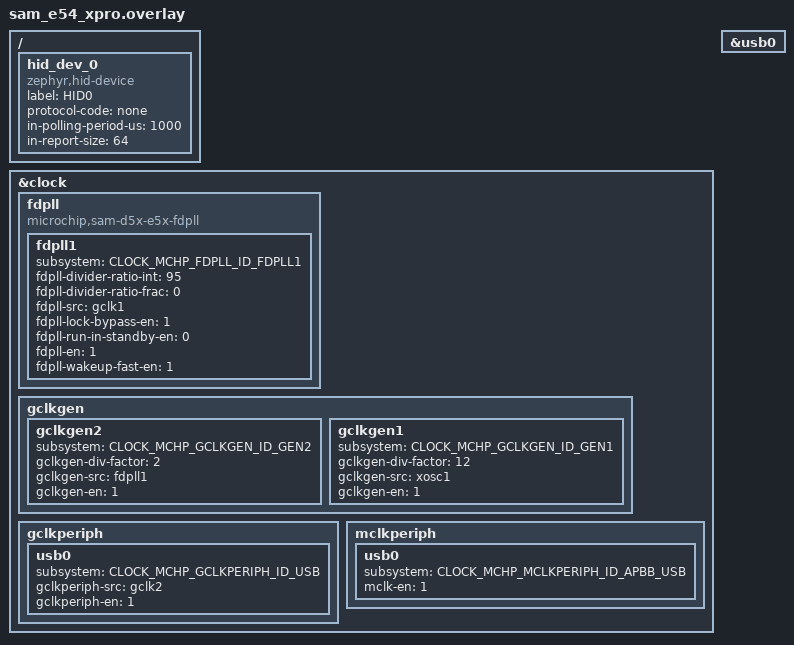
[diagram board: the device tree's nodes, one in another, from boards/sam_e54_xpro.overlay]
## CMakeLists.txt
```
# SPDX-License-Identifier: Apache-2.0

cmake_minimum_required(VERSION 3.28.0)
find_package(Zephyr REQUIRED HINTS $ENV{ZEPHYR_BASE})
project(hid-mouse)

include(${ZEPHYR_BASE}/samples/subsys/usb/common/common.cmake)
FILE(GLOB app_sources src/*.c)
target_sources(app PRIVATE ${app_sources})
```

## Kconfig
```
# Copyright (c) 2019 Nordic Semiconductor ASA
# SPDX-License-Identifier: Apache-2.0

config USB_DEVICE_PID
	default USB_PID_HID_MOUSE_SAMPLE

source "Kconfig.zephyr"
```

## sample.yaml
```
sample:
  name: USB HID mouse sample
common:
  harness: button
  filter: dt_alias_exists("sw0") and dt_alias_exists("led0")
  depends_on:
    - gpio
tests:
  sample.usb.usb_device_next.hid-mouse:
    depends_on:
      - usbd
    integration_platforms:
      - nrf52840dk/nrf52840
      - nrf54h20dk/nrf54h20/cpuapp
      - frdm_k64f
      - stm32f723e_disco
      - nucleo_f413zh
      - mimxrt1060_evk/mimxrt1062/qspi
      - max32690evkit/max32690/m4
    tags: usb
```

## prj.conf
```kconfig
CONFIG_USB_DEVICE_STACK_NEXT=y
CONFIG_CDC_ACM_SERIAL_INITIALIZE_AT_BOOT=n

CONFIG_LOG=y
CONFIG_USBD_LOG_LEVEL_WRN=y
CONFIG_USBD_HID_LOG_LEVEL_WRN=y
CONFIG_UDC_DRIVER_LOG_LEVEL_WRN=y
CONFIG_SAMPLE_USBD_PID=0x0007

CONFIG_GPIO=y
CONFIG_INPUT=y
```

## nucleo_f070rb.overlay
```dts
&usb {
	status = "ok";
};
```

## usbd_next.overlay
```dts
/*
 * Copyright (c) 2023 Nordic Semiconductor ASA
 *
 * SPDX-License-Identifier: Apache-2.0
 */

/ {
	hid_dev_0: hid_dev_0 {
		compatible = "zephyr,hid-device";
		label = "HID0";
		protocol-code = "none";
		in-polling-period-us = <1000>;
		in-report-size = <64>;
	};
};
```

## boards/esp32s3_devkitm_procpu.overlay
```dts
/*
 * Copyright (c) 2025 Espressif Systems (Shanghai) Co., Ltd.
 *
 * SPDX-License-Identifier: Apache-2.0
 */

/ {
	aliases {
		led0 = &blue_led;
	};

	hid_dev_0: hid_dev_0 {
		compatible = "zephyr,hid-device";
		interface-name = "HID0";
		protocol-code = "none";
		in-polling-period-us = <1000>;
		in-report-size = <64>;
	};

	leds {
		compatible = "gpio-leds";

		blue_led: led_0 {
			gpios =  <&gpio0 4 GPIO_ACTIVE_HIGH>;
			label = "Blue - LED0";
		};
	};
};

zephyr_udc0: &usb_otg {
	status = "okay";
};
```

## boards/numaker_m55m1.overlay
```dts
/*
 * SPDX-FileCopyrightText: Copyright (c) 2025 Nuvoton Technology Corporation
 * SPDX-License-Identifier: Apache-2.0
 */

/* Remove USBD */
/delete-node/ &zephyr_udc0;

/* Change to HSUSBD as default */
zephyr_udc0: &hsusbd {
	/* Needn't pinctrl for pins being dedicated */
	status = "okay";
};

/* Enable HXT to clock HSUSB PHY */
&scc {
	hxt = "enable";
};

/* Copy from app.overlay */
/ {
	hid_dev_0: hid_dev_0 {
		compatible = "zephyr,hid-device";
		label = "HID0";
		protocol-code = "none";
		in-polling-period-us = <1000>;
		in-report-size = <64>;
	};
};
```

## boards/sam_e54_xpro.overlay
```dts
/*
 * Copyright (c) 2025 Microchip Technology Inc.
 *
 * SPDX-License-Identifier: Apache-2.0
 */

/ {
	hid_dev_0: hid_dev_0 {
		compatible = "zephyr,hid-device";
		label = "HID0";
		protocol-code = "none";
		in-polling-period-us = <1000>;
		in-report-size = <64>;
	};
};

/* Overlay for clock node */
&clock {
	fdpll {
		compatible = "microchip,sam-d5x-e5x-fdpll";

		fdpll1 {
			subsystem = <CLOCK_MCHP_FDPLL_ID_FDPLL1>;
			fdpll-divider-ratio-int = <95>;
			fdpll-divider-ratio-frac = <0>;
			fdpll-src = "gclk1";
			fdpll-lock-bypass-en = <1>;
			fdpll-run-in-standby-en = <0>;
			fdpll-en = <1>;
			fdpll-wakeup-fast-en = <1>;
		};
	};

	gclkgen {
		gclkgen2 {
			subsystem = <CLOCK_MCHP_GCLKGEN_ID_GEN2>;
			gclkgen-div-factor = <2>;
			gclkgen-src = "fdpll1";
			gclkgen-en = <1>;
		};

		gclkgen1 {
			subsystem = <CLOCK_MCHP_GCLKGEN_ID_GEN1>;
			gclkgen-div-factor = <12>;
			gclkgen-src = "xosc1";
			gclkgen-en = <1>;
		};
	};

	gclkperiph {
		usb0 {
			subsystem = <CLOCK_MCHP_GCLKPERIPH_ID_USB>;
			gclkperiph-src = "gclk2";
			gclkperiph-en = <1>;
		};
	};

	mclkperiph {
		usb0 {
			subsystem = <CLOCK_MCHP_MCLKPERIPH_ID_APBB_USB>;
			mclk-en = <1>;
		};
	};
};

/* Enable USB0 node */
&usb0 {
	status = "okay";
};
```

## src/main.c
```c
/*
 * Copyright (c) 2018 qianfan Zhao
 * Copyright (c) 2018, 2023 Nordic Semiconductor ASA
 *
 * SPDX-License-Identifier: Apache-2.0
 */

#include <sample_usbd.h>

#include <string.h>

#include <zephyr/kernel.h>
#include <zephyr/device.h>
#include <zephyr/drivers/gpio.h>
#include <zephyr/drivers/usb/usb_bc12.h>
#include <zephyr/input/input.h>
#include <zephyr/sys/util.h>

#include <zephyr/usb/usbd.h>
#include <zephyr/usb/class/usbd_hid.h>

#include <zephyr/logging/log.h>
LOG_MODULE_REGISTER(main, LOG_LEVEL_INF);

static const struct device *bc12_dev = DEVICE_DT_GET_OR_NULL(DT_CHOSEN(zephyr_usb_bc12));
static const struct gpio_dt_spec led0 = GPIO_DT_SPEC_GET(DT_ALIAS(led0), gpios);
static const uint8_t hid_report_desc[] = HID_MOUSE_REPORT_DESC(2);

#define MOUSE_BTN_LEFT		0
#define MOUSE_BTN_RIGHT		1

enum mouse_report_idx {
	MOUSE_BTN_REPORT_IDX = 0,
	MOUSE_X_REPORT_IDX = 1,
	MOUSE_Y_REPORT_IDX = 2,
	MOUSE_WHEEL_REPORT_IDX = 3,
	MOUSE_REPORT_COUNT = 4,
};

K_MSGQ_DEFINE(mouse_msgq, MOUSE_REPORT_COUNT, 2, 1);
static bool mouse_ready;

static void input_cb(struct input_event *evt, void *user_data)
{
	static uint8_t tmp[MOUSE_REPORT_COUNT];

	ARG_UNUSED(user_data);

	switch (evt->code) {
	case INPUT_KEY_0:
		WRITE_BIT(tmp[MOUSE_BTN_REPORT_IDX], MOUSE_BTN_LEFT, evt->value);
		break;
	case INPUT_KEY_1:
		WRITE_BIT(tmp[MOUSE_BTN_REPORT_IDX], MOUSE_BTN_RIGHT, evt->value);
		break;
	case INPUT_KEY_2:
		if (evt->value) {
			tmp[MOUSE_X_REPORT_IDX] += 10U;
		}

		break;
	case INPUT_KEY_3:
		if (evt->value) {
			tmp[MOUSE_Y_REPORT_IDX] += 10U;
		}

		break;
	default:
		LOG_INF("Unrecognized input code %u value %d",
			evt->code, evt->value);
		return;
	}

	if (k_msgq_put(&mouse_msgq, tmp, K_NO_WAIT) != 0) {
		LOG_ERR("Failed to put new input event");
	}

	tmp[MOUSE_X_REPORT_IDX] = 0U;
	tmp[MOUSE_Y_REPORT_IDX] = 0U;

}

INPUT_CALLBACK_DEFINE(NULL, input_cb, NULL);

static void mouse_iface_ready(const struct device *dev, const bool ready)
{
	LOG_INF("HID device %s interface is %s",
		dev->name, ready ? "ready" : "not ready");
	mouse_ready = ready;
}

static int mouse_get_report(const struct device *dev,
			 const uint8_t type, const uint8_t id, const uint16_t len,
			 uint8_t *const buf)
{
	LOG_WRN("Get Report not implemented, Type %u ID %u", type, id);

	return 0;
}

struct hid_device_ops mouse_ops = {
	.iface_ready = mouse_iface_ready,
	.get_report = mouse_get_report,
};

static const char *bc12type_to_str(const enum bc12_type type)
{
	switch (type) {
	case BC12_TYPE_NONE:
		return "NONE";
	case BC12_TYPE_SDP:
		return "SDP";
	case BC12_TYPE_DCP:
		return "DCP";
	case BC12_TYPE_CDP:
		return "CDP";
	case BC12_TYPE_PROPRIETARY:
		return "PROPRIETARY";
	case BC12_TYPE_UNKNOWN:
		return "UNKNOWN";
	default:
		return "ERROR";
	}
}

static void bc12_result_cb(const struct device *dev,
			   struct bc12_partner_state *const state,
			   void *const user_data)
{
	if (state->bc12_role != BC12_PORTABLE_DEVICE) {
		LOG_ERR("Unexpected BC role");
		return;
	}

	LOG_INF("New BC state %s (%d uV %d uA)",
		bc12type_to_str(state->type), state->voltage_uv, state->current_ua);

}

int main(void)
{
	struct usbd_context *sample_usbd;
	const struct device *hid_dev;
	int ret;

	if (!gpio_is_ready_dt(&led0)) {
		LOG_ERR("LED device %s is not ready", led0.port->name);
		return 0;
	}

	ret = gpio_pin_configure_dt(&led0, GPIO_OUTPUT);
	if (ret != 0) {
		LOG_ERR("Failed to configure the LED pin, error: %d", ret);
		return 0;
	}

	hid_dev = DEVICE_DT_GET_ONE(zephyr_hid_device);
	if (!device_is_ready(hid_dev)) {
		LOG_ERR("HID Device is not ready");
		return -EIO;
	}

	ret = hid_device_register(hid_dev,
				  hid_report_desc, sizeof(hid_report_desc),
				  &mouse_ops);
	if (ret != 0) {
		LOG_ERR("Failed to register HID Device, %d", ret);
		return ret;
	}

	if (IS_ENABLED(CONFIG_USB_BC12)) {
		if (!device_is_ready(bc12_dev)) {
			LOG_ERR("USB BC1.2 device %s is not ready", bc12_dev->name);
			return -EIO;
		}

		bc12_set_result_cb(bc12_dev, &bc12_result_cb, NULL);
		ret = bc12_set_role(bc12_dev, BC12_PORTABLE_DEVICE);
		if (ret != 0) {
			LOG_ERR("Failed to set BC12 role");
			return -EIO;
		}
	}

	sample_usbd = sample_usbd_init_device(NULL);
	if (sample_usbd == NULL) {
		LOG_ERR("Failed to initialize USB device");
		return -ENODEV;
	}

	ret = usbd_enable(sample_usbd);
	if (ret != 0) {
		LOG_ERR("Failed to enable device support");
		return ret;
	}

	LOG_DBG("USB device support enabled");

	while (true) {
		UDC_STATIC_BUF_DEFINE(report, MOUSE_REPORT_COUNT);

		k_msgq_get(&mouse_msgq, &report, K_FOREVER);

		if (!mouse_ready) {
			LOG_INF("USB HID device is not ready");
			continue;
		}

		ret = hid_device_submit_report(hid_dev, MOUSE_REPORT_COUNT, report);
		if (ret) {
			LOG_ERR("HID submit report error, %d", ret);
		} else {
			/* Toggle LED on sent report */
			(void)gpio_pin_toggle(led0.port, led0.pin);
		}
	}

	return 0;
}
```
